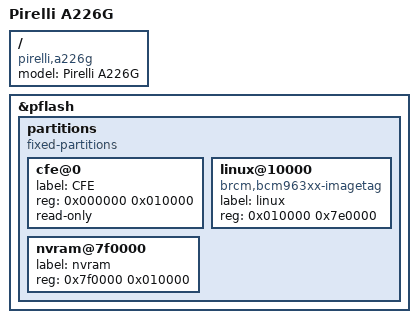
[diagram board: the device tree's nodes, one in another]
#include "bcm6358-pirelli-a226.dtsi"

/ {
	model = "Pirelli A226G";
	compatible = "pirelli,a226g", "brcm,bcm6358";
};

&pflash {
	status = "okay";

	partitions {
		compatible = "fixed-partitions";
		#address-cells = <1>;
		#size-cells = <1>;

		cfe@0 {
			label = "CFE";
			reg = <0x000000 0x010000>;
			read-only;
		};

		linux@10000 {
			label = "linux";
			reg = <0x010000 0x7e0000>;
			compatible = "brcm,bcm963xx-imagetag";
		};

		nvram@7f0000 {
			label = "nvram";
			reg = <0x7f0000 0x010000>;
		};
	};
};
